# STM32H5F5 register map
File version: 1.0
CPU: CM33 r0p0, little endian, MPU, FPU, 4 interrupt priority bits
Registers are 32-bit, read-write, reset 0x0 unless marked. A register's access mark holds for its fields unless they carry their own. Offsets are from the block's base; [hi:lo] are bit positions; {n}, {i} and the like mark numbered series; 'fields as' and 'values as' point back to an identical list; <NAME> marks a mode.

## EXTI — EXTI address block description
Base 0x44022000
Same registers: EXTI_S 0x54022000
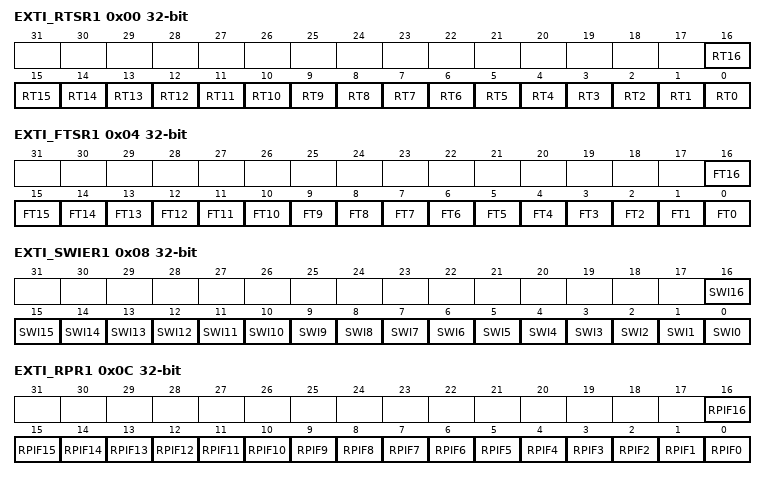
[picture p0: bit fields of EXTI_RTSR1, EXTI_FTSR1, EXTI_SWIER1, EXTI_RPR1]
0x00 EXTI_RTSR1 — EXTI rising trigger selection register
  [all] fields
    0=Rising trigger disabled (for event and interrupt) for input line; 1=Rising trigger enabled (for event and interrupt) for input line
  [n] RT{n} (n=0..16) — Rising trigger event configuration bit of configurable event input x
0x04 EXTI_FTSR1 — EXTI falling trigger selection register
  [all] fields
    0=Falling trigger disabled (for event and Interrupt) for input line; 1=Falling trigger enabled (for event and Interrupt) for input line
  [n] FT{n} (n=0..16) — Falling trigger event configuration bit of configurable event input x
0x08 EXTI_SWIER1 — EXTI software interrupt event register
  [all] fields
    0=Writing 0 has no effect; 1=Writing 1 triggers a rising edge event on event x
  [n] SWI{n} (n=0..16) — Software interrupt on event x
0x0C EXTI_RPR1 — EXTI rising edge pending register
  [all] fields
    0=No rising edge trigger request occurred; 1=Rising edge trigger request occurred
  [n] RPIF{n} (n=0..16) — configurable event inputs x rising edge pending bit
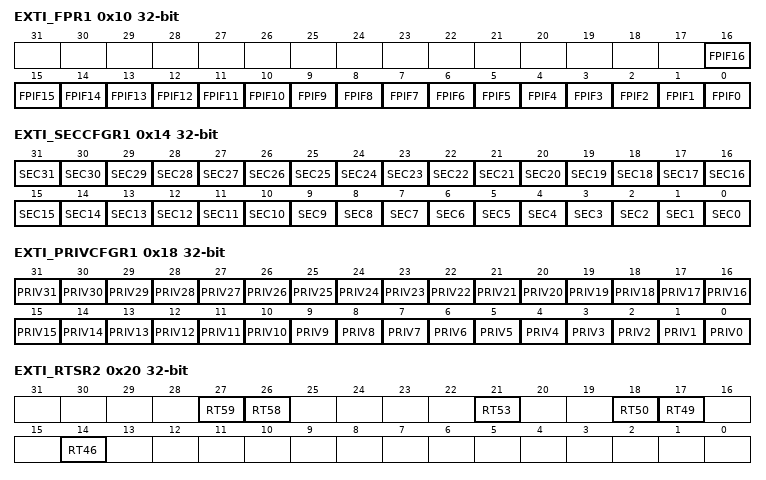
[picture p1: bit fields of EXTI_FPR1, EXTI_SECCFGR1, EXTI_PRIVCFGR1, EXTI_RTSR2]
0x10 EXTI_FPR1 — EXTI falling edge pending register
  [all] fields
    0=No falling edge trigger request occurred; 1=Falling edge trigger request occurred
  [n] FPIF{n} (n=0..16) — configurable event inputs x falling edge pending bit
0x14 EXTI_SECCFGR1 — EXTI security configuration register
  [all] fields
    0=Event security disabled (nonsecure); 1=Event security enabled (secure)
  [n] SEC{n} (n=0..31) — Security enable on event input x
0x18 EXTI_PRIVCFGR1 — EXTI privilege configuration register
  [all] fields
    0=Event privilege disabled (unprivileged); 1=Event privilege enabled (privileged)
  [n] PRIV{n} (n=0..31) — Security enable on event input x
0x20 EXTI_RTSR2 — EXTI rising trigger selection register 2
  [all] fields
    values as the fields of EXTI_RTSR1
  [27] RT59 — Rising trigger event configuration bit of configurable event input x
  [26] RT58 — Rising trigger event configuration bit of configurable event input x
  [21] RT53 — Rising trigger event configuration bit of configurable event input x<sup>(1)</sup>
  [18] RT50 — Rising trigger event configuration bit of configurable event input x<sup>(1)</sup>
  [17] RT49 — Rising trigger event configuration bit of configurable event input x<sup>(1)</sup>
  [14] RT46 — Rising trigger event configuration bit of configurable event input x<sup>(1)</sup>
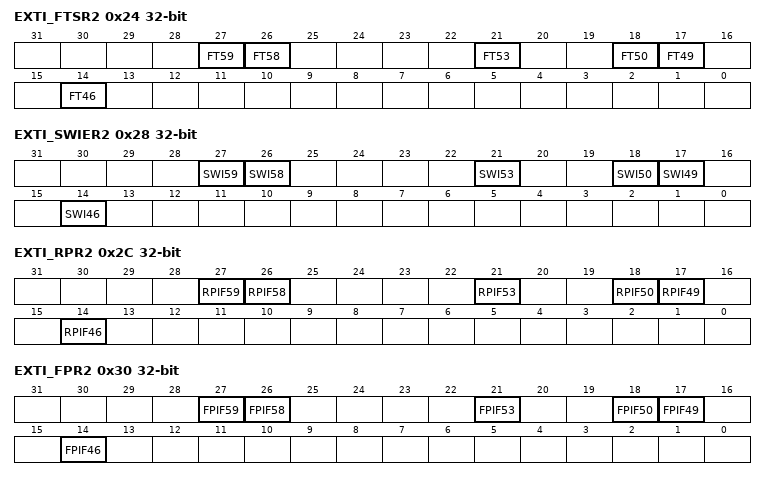
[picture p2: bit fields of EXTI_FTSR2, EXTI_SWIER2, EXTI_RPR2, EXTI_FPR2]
0x24 EXTI_FTSR2 — EXTI falling trigger selection register 2
  [all] fields
    values as the fields of EXTI_FTSR1
  [27] FT59 — Falling trigger event configuration bit of configurable event input x
  [26] FT58 — Falling trigger event configuration bit of configurable event input x
  [21] FT53 — Falling trigger event configuration bit of configurable event input x
  [18] FT50 — Falling trigger event configuration bit of configurable event input x <sup>(3)</sup>
  [17] FT49 — Falling trigger event configuration bit of configurable event input x <sup>(3)</sup>
  [14] FT46 — Falling trigger event configuration bit of configurable event input x <sup>(3)</sup>
0x28 EXTI_SWIER2 — EXTI software interrupt event register 2
  [all] fields
    values as the fields of EXTI_SWIER1
  [27] SWI59 — Software interrupt on event x
  [26] SWI58 — Software interrupt on event x
  [21] SWI53 — Software interrupt on event x
  [18] SWI50 — Software interrupt on event x
  [17] SWI49 — Software interrupt on event x
  [14] SWI46 — Software interrupt on event x
0x2C EXTI_RPR2 — EXTI rising edge pending register 2
  [all] fields
    values as the fields of EXTI_RPR1
  [27] RPIF59 — configurable event inputs x rising edge pending bit
  [26] RPIF58 — configurable event inputs x rising edge pending bit
  [21] RPIF53 — configurable event inputs x rising edge pending bit
  [18] RPIF50 — configurable event inputs x rising edge pending bit
  [17] RPIF49 — configurable event inputs x rising edge pending bit
  [14] RPIF46 — configurable event inputs x rising edge pending bit
0x30 EXTI_FPR2 — EXTI falling edge pending register 2
  [all] fields
    values as the fields of EXTI_FPR1
  [27] FPIF59 — configurable event inputs x falling edge pending bit
  [26] FPIF58 — configurable event inputs x falling edge pending bit
  [21] FPIF53 — configurable event inputs x falling edge pending bit
  [18] FPIF50 — configurable event inputs x falling edge pending bit
  [17] FPIF49 — configurable event inputs x falling edge pending bit
  [14] FPIF46 — configurable event inputs x falling edge pending bit
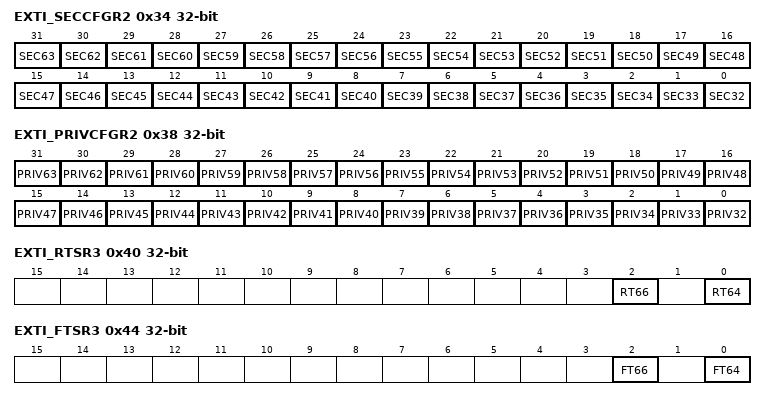
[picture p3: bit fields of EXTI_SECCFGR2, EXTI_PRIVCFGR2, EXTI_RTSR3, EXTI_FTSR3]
0x34 EXTI_SECCFGR2 — EXTI security configuration register 2
  [all] fields
    values as the fields of EXTI_SECCFGR1
  [n-32] SEC{n} (n=32..63) — Security enable on event input x
0x38 EXTI_PRIVCFGR2 — EXTI privilege configuration register 2
  [all] fields
    values as the fields of EXTI_PRIVCFGR1
  [n-32] PRIV{n} (n=32..63) — Security enable on event input x
0x40 EXTI_RTSR3 — EXTI rising trigger selection register 3
  [2] RT66 — Rising trigger event configuration bit of configurable event input x<sup>(1)</sup>
    values as the fields of EXTI_RTSR1
  [0] RT64 — Rising trigger event configuration bit of configurable event input x<sup>(1)</sup>
    values as the fields of EXTI_RTSR1
0x44 EXTI_FTSR3 — EXTI falling trigger selection register 3
  [2] FT66 — Falling trigger event configuration bit of configurable event input x
    values as the fields of EXTI_FTSR1
  [0] FT64 — Falling trigger event configuration bit of configurable event input x
    values as the fields of EXTI_FTSR1
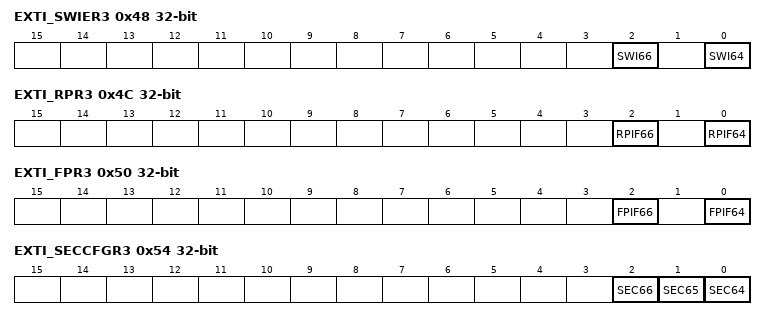
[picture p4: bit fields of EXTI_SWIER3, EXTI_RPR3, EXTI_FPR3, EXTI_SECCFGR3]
0x48 EXTI_SWIER3 — EXTI software interrupt event register 3
  [2] SWI66 — Software interrupt on event x
    values as the fields of EXTI_SWIER1
  [0] SWI64 — Software interrupt on event x
    values as the fields of EXTI_SWIER1
0x4C EXTI_RPR3 — EXTI rising edge pending register 3
  [2] RPIF66 — configurable event inputs x rising edge pending bit
    values as the fields of EXTI_RPR1
  [0] RPIF64 — configurable event inputs x rising edge pending bit
    values as the fields of EXTI_RPR1
0x50 EXTI_FPR3 — EXTI falling edge pending register 3
  [2] FPIF66 — configurable event inputs x falling edge pending bit
    values as the fields of EXTI_FPR1
  [0] FPIF64 — configurable event inputs x falling edge pending bit
    values as the fields of EXTI_FPR1
0x54 EXTI_SECCFGR3 — EXTI security configuration register 3
  [all] fields
    values as the fields of EXTI_SECCFGR1
  [2] SEC66 — Security enable on event input x
  [1] SEC65 — Security enable on event input x
  [0] SEC64 — Security enable on event input x
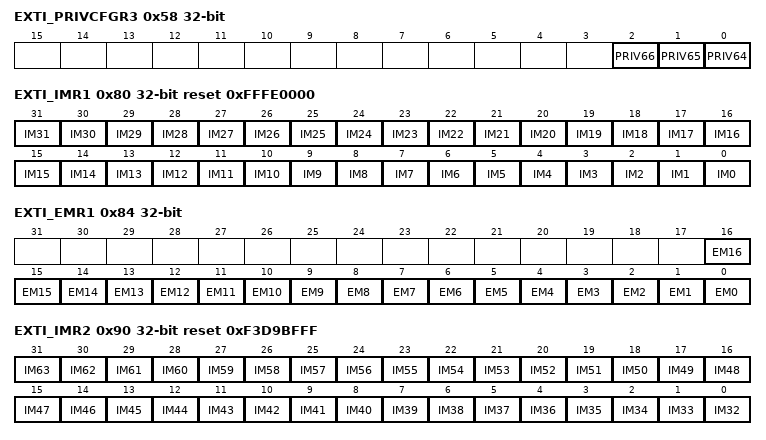
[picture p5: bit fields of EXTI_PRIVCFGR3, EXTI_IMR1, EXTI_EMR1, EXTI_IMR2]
0x58 EXTI_PRIVCFGR3 — EXTI privilege configuration register 3
  [all] fields
    values as the fields of EXTI_PRIVCFGR1
  [2] PRIV66 — Security enable on event input x
  [1] PRIV65 — Security enable on event input x
  [0] PRIV64 — Security enable on event input x
0x70 EXTI_LOCKR — EXTI lock register
  [0] LOCK — Global security and privilege configuration registers (EXTI_SECCFGR and EXTI_PRIVCFGR) lock
    0=Security and privilege configuration open, can be modified; 1=Security and privilege configuration locked, can no longer be modified
0x80 EXTI_IMR1 reset 0xFFFE0000 — EXTI CPU wake-up with interrupt mask register
  [all] fields
    0=Wake-up with interrupt request from input event x is masked; 1=Wake-up with interrupt request from input event x is unmasked
  [n] IM{n} (n=0..31) — CPU wake-up with interrupt mask on event input x
0x84 EXTI_EMR1 — EXTI CPU wake-up with event mask register
  [all] fields
    0=Wake-up with event generation from Line x is masked; 1=Wake-up with event generation from Line x is unmasked
  [n] EM{n} (n=0..16) — CPU wake-up with event generation mask on event input x
0x90 EXTI_IMR2 reset 0xF3D9BFFF — EXTI CPU wake-up with interrupt mask register 2
  [all] fields
    values as the fields of EXTI_IMR1
  [n-32] IM{n} (n=32..63) — CPU wake-up with interrupt mask on event input x
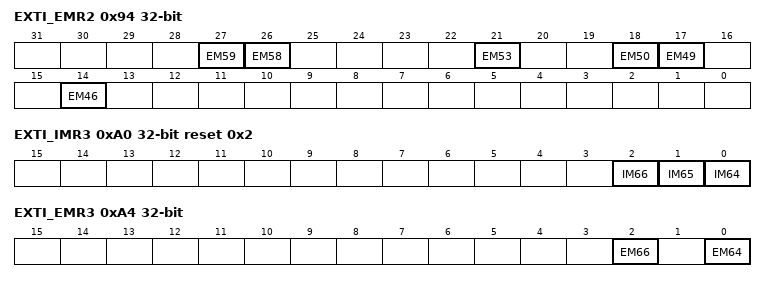
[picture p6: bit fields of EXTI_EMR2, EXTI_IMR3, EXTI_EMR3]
0x94 EXTI_EMR2 — EXTI CPU wake-up with event mask register 2
  [all] fields
    values as the fields of EXTI_EMR1
  [27] EM59 — CPU wake-up with event generation mask on event input x
  [26] EM58 — CPU wake-up with event generation mask on event input x
  [21] EM53 — CPU wake-up with event generation mask on event input
  [18] EM50 — CPU wake-up with event generation mask on event input x
  [17] EM49 — CPU wake-up with event generation mask on event input x
  [14] EM46 — CPU wake-up with event generation mask on event input
0xA0 EXTI_IMR3 reset 0x2 — EXTI CPU wake-up with interrupt mask register 3
  [all] fields
    values as the fields of EXTI_IMR1
  [2] IM66 — CPU wake-up with interrupt mask on event input x
  [1] IM65 — CPU wake-up with interrupt mask on event input x
  [0] IM64 — CPU wake-up with interrupt mask on event input x
0xA4 EXTI_EMR3 — EXTI CPU wake-up with event mask register 3
  [2] EM66 — CPU wake-up with event generation mask on event input
    values as the fields of EXTI_EMR1
  [0] EM64 — CPU wake-up with event generation mask on event input
    values as the fields of EXTI_EMR1
